# SA3_SS_SA_UL_0_SA_UL_PRIMARY_40900000h register map
Vendor: Texas Instruments
Peripheral module from a debugger description file (folder AM275x).
Registers are 32-bit, read-only, reset 0x0 unless marked. A register's access mark holds for its fields unless they carry their own. Offsets are as the file gives them; lines under a group give offsets from that group; [hi:lo] are bit positions; {n}, {i} and the like mark numbered series; 'fields as' and 'values as' point back to an identical list; <NAME> marks a mode.

## sa_ul_primary
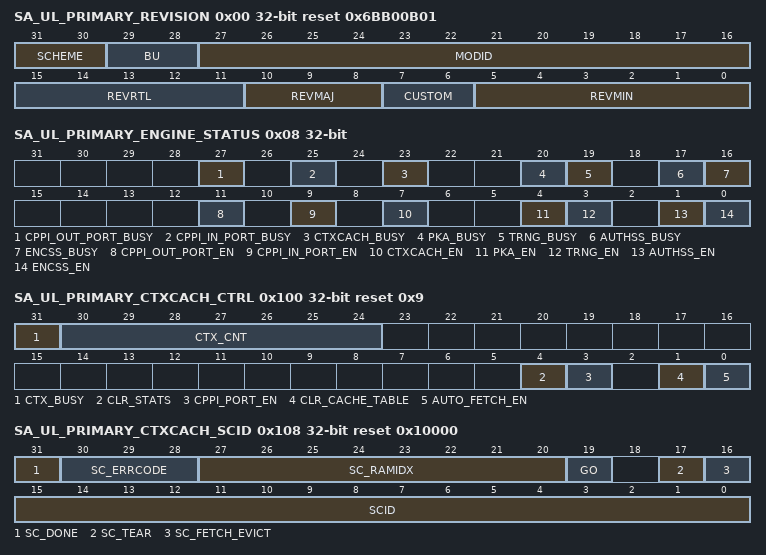
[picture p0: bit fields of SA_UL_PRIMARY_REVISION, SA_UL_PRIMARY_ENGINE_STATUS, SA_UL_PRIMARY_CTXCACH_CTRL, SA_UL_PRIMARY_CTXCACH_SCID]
0x00 SA_UL_PRIMARY_REVISION reset 0x6BB00B01 — Version and Identification Register
  [31:30] SCHEME — Scheme Reset Source: rst_mod_g_rst_n
  [29:28] BU — Business Unit Reset Source: rst_mod_g_rst_n
  [27:16] MODID — Module ID Reset Source: rst_mod_g_rst_n
  [15:11] REVRTL — RTL revision Reset Source: rst_mod_g_rst_n
  [10:8] REVMAJ — Major revision Reset Source: rst_mod_g_rst_n
  [7:6] CUSTOM — Custom revision Reset Source: rst_mod_g_rst_n
  [5:0] REVMIN — Minor Revision Reset Source: rst_mod_g_rst_n
0x08 SA_UL_PRIMARY_ENGINE_STATUS — The engine_status register contains the enable and busy status for every crypto core
  [27] CPPI_OUT_PORT_BUSY — PSI output port busy status bit Reset Source: rst_mod_g_rst_n
  [25] CPPI_IN_PORT_BUSY — PSI input port busy status bit Reset Source: rst_mod_g_rst_n
  [23] CTXCACH_BUSY — ContextCache module busy status bit Reset Source: rst_mod_g_rst_n
  [20] PKA_BUSY — PKA module busy status bit Reset Source: rst_mod_g_rst_n
  [19] TRNG_BUSY — Random number generator module busy status bit Reset Source: rst_mod_g_rst_n
  [17] AUTHSS_BUSY — Authentication module busy status bit Reset Source: rst_mod_g_rst_n
  [16] ENCSS_BUSY — Encryption module busy status bit Reset Source: rst_mod_g_rst_n
  [11] CPPI_OUT_PORT_EN — Enable indicator for the output streaming interface Reset Source: rst_mod_g_rst_n
  [9] CPPI_IN_PORT_EN — Enable indicator for the input streaming interface Reset Source: rst_mod_g_rst_n
  [7] CTXCACH_EN — Enable indicator for context cache engine Reset Source: rst_mod_g_rst_n
  [4] PKA_EN — Enable indicator for PKA engine Reset Source: rst_mod_g_rst_n
  [3] TRNG_EN — Enable indicator for TRNG engine Reset Source: rst_mod_g_rst_n
  [1] AUTHSS_EN — Enable indicator for authentication engine Reset Source: rst_mod_g_rst_n
  [0] ENCSS_EN — Enable indicator for encryption engine Reset Source: rst_mod_g_rst_n
0x14 SA_UL_PRIMARY_CPPI_FLOWID rw — The flowid register is no longer used as the DMA software info word 2 must carry this information
  [7:0] CPPI_FLOWID — cppi default flow id Reset Source: rst_mod_g_rst_n
0x1C SA_UL_PRIMARY_DEFAULT_ENG_ID rw reset 0x14 — The default_eng_id contains the first engine only if default engine id code is in the DMA software info word 0
  [4:0] DEFAULT_ENG_ID — default engine id Reset Source: rst_mod_g_rst_n
0x100 SA_UL_PRIMARY_CTXCACH_CTRL access per field reset 0x9 — The ctxcach_ctrl contains some control and status of the context cache engine
  [31] CTX_BUSY ro — context busy Reset Source: rst_mod_g_rst_n
  [30:24] CTX_CNT ro — context counts Reset Source: rst_mod_g_rst_n
  [4] CLR_STATS rw — clear stats Reset Source: rst_mod_g_rst_n
  [3] CPPI_PORT_EN rw — enable cppi ctxcach port Reset Source: rst_mod_g_rst_n
  [1] CLR_CACHE_TABLE ro — clear cache table Reset Source: rst_mod_g_rst_n
  [0] AUTO_FETCH_EN ro — enable auto fetch Reset Source: rst_mod_g_rst_n
0x108 SA_UL_PRIMARY_CTXCACH_SCID access per field reset 0x10000 — The ctxcach_scid register is no longer used as context operation is fully under hardware control
  [31] SC_DONE ro — done bit indicator Reset Source: rst_mod_g_rst_n
  [30:28] SC_ERRCODE ro — pass / error code result Reset Source: rst_mod_g_rst_n
  [27:20] SC_RAMIDX ro — ram index result Reset Source: rst_mod_g_rst_n
  [19] GO rw — execute Reset Source: rst_mod_g_rst_n
  [17] SC_TEAR rw — 1:tear Reset Source: rst_mod_g_rst_n
  [16] SC_FETCH_EVICT ro — always read 1:evict Reset Source: rst_mod_g_rst_n
  [15:0] SCID rw — SCID for mmr based evict Reset Source: rst_mod_g_rst_n
0x10C SA_UL_PRIMARY_CTXCACH_MISSCNT — The ctxcach_misscnt contains the number of how many misses that trigger context fetch
  [31:0] CTX_MISSCNT — cache miss counter Reset Source: rst_mod_g_rst_n
